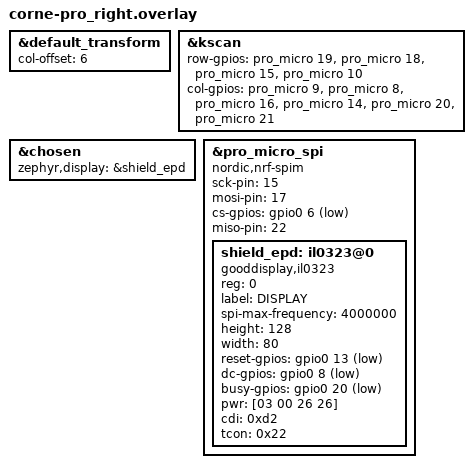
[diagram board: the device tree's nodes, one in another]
/*
 * Copyright (c) 2020 The ZMK Contributors
 *
 * SPDX-License-Identifier: MIT
 */

#include "corne-pro.dtsi"

// adjust matrix transform for pepripheral split
&default_transform {
	col-offset = <6>;
};

// setup kscan pins
&kscan {
  row-gpios
	  = <&pro_micro 19  (GPIO_ACTIVE_HIGH | GPIO_PULL_DOWN)>
		, <&pro_micro 18  (GPIO_ACTIVE_HIGH | GPIO_PULL_DOWN)>
		, <&pro_micro 15 (GPIO_ACTIVE_HIGH | GPIO_PULL_DOWN)>
		, <&pro_micro 10 (GPIO_ACTIVE_HIGH | GPIO_PULL_DOWN)>
		;

	col-gpios
		= <&pro_micro  9 GPIO_ACTIVE_HIGH>
		, <&pro_micro  8 GPIO_ACTIVE_HIGH>
		, <&pro_micro 16 GPIO_ACTIVE_HIGH>
		, <&pro_micro 14 GPIO_ACTIVE_HIGH>
		, <&pro_micro 20 GPIO_ACTIVE_HIGH>
		, <&pro_micro 21 GPIO_ACTIVE_HIGH>
		;
};

/* display */
&chosen {
  zephyr,display = &shield_epd;
};

&pro_micro_spi {
  compatible = "nordic,nrf-spim";
  sck-pin = <15>;
  mosi-pin = <17>;
  cs-gpios = <&gpio0 6 GPIO_ACTIVE_LOW>;
  // not used, but required by spim binding; can be reuesd in the keymap for normal key press
  miso-pin = <22>;

  // activate this device
  status = "okay";

  // spi-device: gooddisplay GDEW0102T4
  shield_epd: il0323@0 {
    compatible = "gooddisplay,il0323";
    reg = <0>;
    label = "DISPLAY";
    spi-max-frequency = <4000000>;

    height = <128>;
    width = <80>;
    reset-gpios = <&gpio0 13  GPIO_ACTIVE_LOW>;
    dc-gpios    = <&gpio0  8  GPIO_ACTIVE_LOW>;
    busy-gpios  = <&gpio0 20  GPIO_ACTIVE_LOW>;
    pwr = [03 00 26 26];
    cdi = <0xd2>;
    tcon = <0x22>;
  }; 
};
